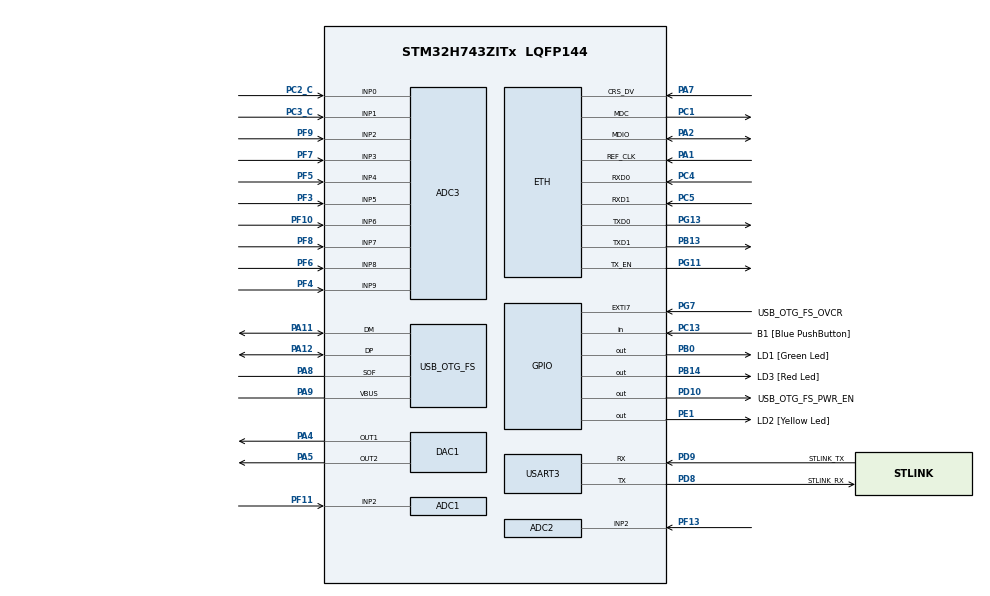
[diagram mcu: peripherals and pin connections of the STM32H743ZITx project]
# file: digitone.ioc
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ADC1.Channel-0\#ChannelRegularConversion=ADC_CHANNEL_2
ADC1.ExternalTrigConv=ADC_EXTERNALTRIG_T6_TRGO
ADC1.NbrOfConversionFlag=1
ADC1.OffsetNumber-0\#ChannelRegularConversion=ADC_OFFSET_NONE
ADC1.OffsetSignedSaturation-0\#ChannelRegularConversion=DISABLE
ADC1.Rank-0\#ChannelRegularConversion=1
ADC1.SamplingTime-0\#ChannelRegularConversion=ADC_SAMPLETIME_1CYCLE_5
ADC1.master=1
ADC2.Channel-0\#ChannelRegularConversion=ADC_CHANNEL_2
ADC2.ExternalTrigConv=ADC_EXTERNALTRIG_T6_TRGO
ADC2.NbrOfConversionFlag=1
ADC2.OffsetNumber-0\#ChannelRegularConversion=ADC_OFFSET_NONE
ADC2.OffsetSignedSaturation-0\#ChannelRegularConversion=DISABLE
ADC2.Rank-0\#ChannelRegularConversion=1
ADC2.SamplingTime-0\#ChannelRegularConversion=ADC_SAMPLETIME_1CYCLE_5
ADC3.Channel-0\#ChannelRegularConversion=ADC_CHANNEL_0
ADC3.Channel-1\#ChannelRegularConversion=ADC_CHANNEL_1
ADC3.Channel-2\#ChannelRegularConversion=ADC_CHANNEL_2
ADC3.Channel-3\#ChannelRegularConversion=ADC_CHANNEL_3
ADC3.Channel-4\#ChannelRegularConversion=ADC_CHANNEL_4
ADC3.Channel-5\#ChannelRegularConversion=ADC_CHANNEL_5
ADC3.Channel-6\#ChannelRegularConversion=ADC_CHANNEL_6
ADC3.Channel-7\#ChannelRegularConversion=ADC_CHANNEL_7
ADC3.Channel-8\#ChannelRegularConversion=ADC_CHANNEL_8
ADC3.Channel-9\#ChannelRegularConversion=ADC_CHANNEL_9
ADC3.EOCSelection=ADC_EOC_SEQ_CONV
ADC3.ExternalTrigConv=ADC_EXTERNALTRIG_T3_TRGO
ADC3.NbrOfConversion=10
ADC3.NbrOfConversionFlag=1
ADC3.OffsetNumber-0\#ChannelRegularConversion=ADC_OFFSET_NONE
ADC3.OffsetNumber-1\#ChannelRegularConversion=ADC_OFFSET_NONE
ADC3.OffsetNumber-2\#ChannelRegularConversion=ADC_OFFSET_NONE
ADC3.OffsetNumber-3\#ChannelRegularConversion=ADC_OFFSET_NONE
ADC3.OffsetNumber-4\#ChannelRegularConversion=ADC_OFFSET_NONE
ADC3.OffsetNumber-5\#ChannelRegularConversion=ADC_OFFSET_NONE
ADC3.OffsetNumber-6\#ChannelRegularConversion=ADC_OFFSET_NONE
ADC3.OffsetNumber-7\#ChannelRegularConversion=ADC_OFFSET_NONE
ADC3.OffsetNumber-8\#ChannelRegularConversion=ADC_OFFSET_NONE
ADC3.OffsetNumber-9\#ChannelRegularConversion=ADC_OFFSET_NONE
ADC3.OffsetSignedSaturation-0\#ChannelRegularConversion=DISABLE
ADC3.OffsetSignedSaturation-1\#ChannelRegularConversion=DISABLE
ADC3.OffsetSignedSaturation-2\#ChannelRegularConversion=DISABLE
ADC3.OffsetSignedSaturation-3\#ChannelRegularConversion=DISABLE
ADC3.OffsetSignedSaturation-4\#ChannelRegularConversion=DISABLE
ADC3.OffsetSignedSaturation-5\#ChannelRegularConversion=DISABLE
ADC3.OffsetSignedSaturation-6\#ChannelRegularConversion=DISABLE
ADC3.OffsetSignedSaturation-7\#ChannelRegularConversion=DISABLE
ADC3.OffsetSignedSaturation-8\#ChannelRegularConversion=DISABLE
ADC3.OffsetSignedSaturation-9\#ChannelRegularConversion=DISABLE
ADC3.Rank-0\#ChannelRegularConversion=1
ADC3.Rank-1\#ChannelRegularConversion=2
ADC3.Rank-2\#ChannelRegularConversion=3
ADC3.Rank-3\#ChannelRegularConversion=4
ADC3.Rank-4\#ChannelRegularConversion=5
ADC3.Rank-5\#ChannelRegularConversion=6
ADC3.Rank-6\#ChannelRegularConversion=7
ADC3.Rank-7\#ChannelRegularConversion=8
ADC3.Rank-8\#ChannelRegularConversion=9
ADC3.Rank-9\#ChannelRegularConversion=10
ADC3.SamplingTime-0\#ChannelRegularConversion=ADC_SAMPLETIME_1CYCLE_5
ADC3.SamplingTime-1\#ChannelRegularConversion=ADC_SAMPLETIME_1CYCLE_5
ADC3.SamplingTime-2\#ChannelRegularConversion=ADC_SAMPLETIME_1CYCLE_5
ADC3.SamplingTime-3\#ChannelRegularConversion=ADC_SAMPLETIME_1CYCLE_5
ADC3.SamplingTime-4\#ChannelRegularConversion=ADC_SAMPLETIME_1CYCLE_5
ADC3.SamplingTime-5\#ChannelRegularConversion=ADC_SAMPLETIME_1CYCLE_5
ADC3.SamplingTime-6\#ChannelRegularConversion=ADC_SAMPLETIME_1CYCLE_5
ADC3.SamplingTime-7\#ChannelRegularConversion=ADC_SAMPLETIME_1CYCLE_5
ADC3.SamplingTime-8\#ChannelRegularConversion=ADC_SAMPLETIME_1CYCLE_5
ADC3.SamplingTime-9\#ChannelRegularConversion=ADC_SAMPLETIME_1CYCLE_5
Bdma.ADC3.0.Direction=DMA_PERIPH_TO_MEMORY
Bdma.ADC3.0.EventEnable=DISABLE
Bdma.ADC3.0.Instance=BDMA_Channel0
Bdma.ADC3.0.MemDataAlignment=DMA_MDATAALIGN_HALFWORD
Bdma.ADC3.0.MemInc=DMA_MINC_ENABLE
Bdma.ADC3.0.Mode=DMA_CIRCULAR
Bdma.ADC3.0.PeriphDataAlignment=DMA_PDATAALIGN_HALFWORD
Bdma.ADC3.0.PeriphInc=DMA_PINC_DISABLE
Bdma.ADC3.0.Polarity=HAL_DMAMUX_REQ_GEN_RISING
Bdma.ADC3.0.Priority=DMA_PRIORITY_LOW
Bdma.ADC3.0.RequestNumber=1
Bdma.ADC3.0.SignalID=NONE
Bdma.ADC3.0.SyncEnable=DISABLE
Bdma.ADC3.0.SyncPolarity=HAL_DMAMUX_SYNC_NO_EVENT
Bdma.ADC3.0.SyncRequestNumber=1
Bdma.ADC3.0.SyncSignalID=NONE
Bdma.Request0=ADC3
Bdma.RequestsNb=1
DAC1.DAC_Channel-DAC_OUT1=DAC_CHANNEL_1
DAC1.DAC_Channel-DAC_OUT2=DAC_CHANNEL_2
Dma.ADC1.0.Direction=DMA_PERIPH_TO_MEMORY
Dma.ADC1.0.EventEnable=DISABLE
Dma.ADC1.0.FIFOMode=DMA_FIFOMODE_DISABLE
Dma.ADC1.0.Instance=DMA1_Stream0
Dma.ADC1.0.MemDataAlignment=DMA_MDATAALIGN_HALFWORD
Dma.ADC1.0.MemInc=DMA_MINC_ENABLE
Dma.ADC1.0.Mode=DMA_CIRCULAR
Dma.ADC1.0.PeriphDataAlignment=DMA_PDATAALIGN_HALFWORD
Dma.ADC1.0.PeriphInc=DMA_PINC_DISABLE
Dma.ADC1.0.Polarity=HAL_DMAMUX_REQ_GEN_RISING
Dma.ADC1.0.Priority=DMA_PRIORITY_LOW
Dma.ADC1.0.RequestNumber=1
Dma.ADC1.0.SignalID=NONE
Dma.ADC1.0.SyncEnable=DISABLE
Dma.ADC1.0.SyncPolarity=HAL_DMAMUX_SYNC_NO_EVENT
Dma.ADC1.0.SyncRequestNumber=1
Dma.ADC1.0.SyncSignalID=NONE
Dma.ADC2.1.Direction=DMA_PERIPH_TO_MEMORY
Dma.ADC2.1.EventEnable=DISABLE
Dma.ADC2.1.FIFOMode=DMA_FIFOMODE_DISABLE
Dma.ADC2.1.Instance=DMA1_Stream1
Dma.ADC2.1.MemDataAlignment=DMA_MDATAALIGN_HALFWORD
Dma.ADC2.1.MemInc=DMA_MINC_ENABLE
Dma.ADC2.1.Mode=DMA_CIRCULAR
Dma.ADC2.1.PeriphDataAlignment=DMA_PDATAALIGN_HALFWORD
Dma.ADC2.1.PeriphInc=DMA_PINC_DISABLE
Dma.ADC2.1.Polarity=HAL_DMAMUX_REQ_GEN_RISING
Dma.ADC2.1.Priority=DMA_PRIORITY_HIGH
Dma.ADC2.1.RequestNumber=1
Dma.ADC2.1.SignalID=NONE
Dma.ADC2.1.SyncEnable=DISABLE
Dma.ADC2.1.SyncPolarity=HAL_DMAMUX_SYNC_NO_EVENT
Dma.ADC2.1.SyncRequestNumber=1
Dma.ADC2.1.SyncSignalID=NONE
Dma.DAC1_CH1.2.Direction=DMA_MEMORY_TO_PERIPH
Dma.DAC1_CH1.2.EventEnable=DISABLE
Dma.DAC1_CH1.2.FIFOMode=DMA_FIFOMODE_DISABLE
Dma.DAC1_CH1.2.Instance=DMA1_Stream2
Dma.DAC1_CH1.2.MemDataAlignment=DMA_MDATAALIGN_HALFWORD
Dma.DAC1_CH1.2.MemInc=DMA_MINC_ENABLE
Dma.DAC1_CH1.2.Mode=DMA_CIRCULAR
Dma.DAC1_CH1.2.PeriphDataAlignment=DMA_PDATAALIGN_HALFWORD
Dma.DAC1_CH1.2.PeriphInc=DMA_PINC_DISABLE
Dma.DAC1_CH1.2.Polarity=HAL_DMAMUX_REQ_GEN_RISING
Dma.DAC1_CH1.2.Priority=DMA_PRIORITY_HIGH
Dma.DAC1_CH1.2.RequestNumber=1
Dma.DAC1_CH1.2.SignalID=NONE
Dma.DAC1_CH1.2.SyncEnable=DISABLE
Dma.DAC1_CH1.2.SyncPolarity=HAL_DMAMUX_SYNC_NO_EVENT
Dma.DAC1_CH1.2.SyncRequestNumber=1
Dma.DAC1_CH1.2.SyncSignalID=NONE
Dma.DAC1_CH2.3.Direction=DMA_MEMORY_TO_PERIPH
Dma.DAC1_CH2.3.EventEnable=DISABLE
Dma.DAC1_CH2.3.FIFOMode=DMA_FIFOMODE_DISABLE
Dma.DAC1_CH2.3.Instance=DMA1_Stream3
Dma.DAC1_CH2.3.MemDataAlignment=DMA_MDATAALIGN_HALFWORD
Dma.DAC1_CH2.3.MemInc=DMA_MINC_ENABLE
Dma.DAC1_CH2.3.Mode=DMA_CIRCULAR
Dma.DAC1_CH2.3.PeriphDataAlignment=DMA_PDATAALIGN_HALFWORD
Dma.DAC1_CH2.3.PeriphInc=DMA_PINC_DISABLE
Dma.DAC1_CH2.3.Polarity=HAL_DMAMUX_REQ_GEN_RISING
Dma.DAC1_CH2.3.Priority=DMA_PRIORITY_LOW
Dma.DAC1_CH2.3.RequestNumber=1
Dma.DAC1_CH2.3.SignalID=NONE
Dma.DAC1_CH2.3.SyncEnable=DISABLE
Dma.DAC1_CH2.3.SyncPolarity=HAL_DMAMUX_SYNC_NO_EVENT
Dma.DAC1_CH2.3.SyncRequestNumber=1
Dma.DAC1_CH2.3.SyncSignalID=NONE
Dma.Request0=ADC1
Dma.Request1=ADC2
Dma.Request2=DAC1_CH1
Dma.Request3=DAC1_CH2
ETH.MediaInterface=HAL_ETH_RMII_MODE
Mcu.Family=STM32H7
Mcu.Name=STM32H743ZITx
Mcu.Package=LQFP144
NVIC.BDMA_Channel0_IRQn=true\:0\:0\:false\:false\:true\:false\:true\:true
NVIC.DMA1_Stream0_IRQn=true\:0\:0\:false\:false\:true\:false\:true\:true
NVIC.DMA1_Stream1_IRQn=true\:0\:0\:false\:false\:true\:false\:true\:true
NVIC.DMA1_Stream2_IRQn=true\:0\:0\:false\:false\:true\:false\:true\:true
NVIC.DMA1_Stream3_IRQn=true\:0\:0\:false\:false\:true\:false\:true\:true
NVIC.PriorityGroup=NVIC_PRIORITYGROUP_4
PA1.Mode=RMII
PA1.Signal=ETH_REF_CLK
PA11.Mode=Device_Only
PA11.Signal=USB_OTG_FS_DM
PA12.Mode=Device_Only
PA12.Signal=USB_OTG_FS_DP
PA2.Mode=RMII
PA2.Signal=ETH_MDIO
PA4.Signal=COMP_DAC11_group
PA5.Signal=COMP_DAC12_group
PA7.Mode=RMII
PA7.Signal=ETH_CRS_DV
PA8.Mode=Activate_SOF_FS
PA8.Signal=USB_OTG_FS_SOF
PA9.Mode=Activate_VBUS
PA9.Signal=USB_OTG_FS_VBUS
PB0.GPIO_Label=LD1 [Green Led]
PB0.Signal=GPIO_Output
PB13.Mode=RMII
PB13.Signal=ETH_TXD1
PB14.GPIO_Label=LD3 [Red Led]
PB14.Signal=GPIO_Output
PC1.Mode=RMII
PC1.Signal=ETH_MDC
PC13.GPIO_Label=B1 [Blue PushButton]
PC13.Signal=GPIO_Input
PC14-OSC32_IN\ (OSC32_IN).Mode=LSE-External-Oscillator
PC14-OSC32_IN\ (OSC32_IN).Signal=RCC_OSC32_IN
PC15-OSC32_OUT\ (OSC32_OUT).Mode=LSE-External-Oscillator
PC15-OSC32_OUT\ (OSC32_OUT).Signal=RCC_OSC32_OUT
PC2_C.Mode=IN0-Single-Ended
PC2_C.Signal=ADC3_INP0
PC3_C.Mode=IN1-Single-Ended
PC3_C.Signal=ADC3_INP1
PC4.Mode=RMII
PC4.Signal=ETH_RXD0
PC5.Mode=RMII
PC5.Signal=ETH_RXD1
PD10.GPIO_Label=USB_OTG_FS_PWR_EN
PD10.Signal=GPIO_Output
PD8.GPIO_Label=STLINK_RX
PD8.Mode=Asynchronous
PD8.Signal=USART3_TX
PD9.GPIO_Label=STLINK_TX
PD9.Mode=Asynchronous
PD9.Signal=USART3_RX
PE1.GPIO_Label=LD2 [Yellow Led]
PE1.Signal=GPIO_Output
PF10.Mode=IN6-Single-Ended
PF10.Signal=ADC3_INP6
PF11.Mode=IN2-Single-Ended
PF11.Signal=ADC1_INP2
PF13.Mode=IN2-Single-Ended
PF13.Signal=ADC2_INP2
PF3.Mode=IN5-Single-Ended
PF3.Signal=ADC3_INP5
PF4.Mode=IN9-Single-Ended
PF4.Signal=ADC3_INP9
PF5.Mode=IN4-Single-Ended
PF5.Signal=ADC3_INP4
PF6.Mode=IN8-Single-Ended
PF6.Signal=ADC3_INP8
PF7.Mode=IN3-Single-Ended
PF7.Signal=ADC3_INP3
PF8.Mode=IN7-Single-Ended
PF8.Signal=ADC3_INP7
PF9.Mode=IN2-Single-Ended
PF9.Signal=ADC3_INP2
PG11.Mode=RMII
PG11.Signal=ETH_TX_EN
PG13.Mode=RMII
PG13.Signal=ETH_TXD0
PG7.GPIO_Label=USB_OTG_FS_OVCR
PG7.Signal=GPXTI7
PH0-OSC_IN\ (PH0).Mode=HSE-External-Clock-Source
PH0-OSC_IN\ (PH0).Signal=RCC_OSC_IN
PH1-OSC_OUT\ (PH1).Signal=RCC_OSC_OUT
ProjectManager.HeapSize=0x200
ProjectManager.StackSize=0x400
ProjectManager.TargetToolchain=STM32CubeIDE
RCC.ADCFreq_Value=76000000
RCC.APB1Freq_Value=64000000
RCC.APB2Freq_Value=64000000
RCC.APB3Freq_Value=64000000
RCC.APB4Freq_Value=64000000
RCC.CortexFreq_Value=64000000
RCC.DIVM1=1
RCC.DIVM2=1
RCC.DIVN1=24
RCC.DIVN2=19
RCC.DIVQ1=4
RCC.HCLKFreq_Value=64000000
RCC.HSE_VALUE=8000000
RCC.PLLFRACN=0
RCC.PWR_Regulator_Voltage_Scale=PWR_REGULATOR_VOLTAGE_SCALE2
RCC.SYSCLKFreq_VALUE=64000000
RCC.USBFreq_Value=48000000
SH.COMP_DAC11_group.0=DAC1_OUT1,DAC_OUT1
SH.COMP_DAC12_group.0=DAC1_OUT2,DAC_OUT2
TIM3.Period=1024-1
TIM3.Prescaler=64-1
TIM3.TIM_MasterOutputTrigger=TIM_TRGO_UPDATE
TIM6.Period=128-1
TIM6.Prescaler=8-1
TIM6.TIM_MasterOutputTrigger=TIM_TRGO_UPDATE
USART3.VirtualMode-Asynchronous=VM_ASYNC
USB_OTG_FS.VirtualMode=Device_Only
VP_TIM3_VS_ClockSourceINT.Mode=Internal
VP_TIM6_VS_ClockSourceINT.Mode=Enable_Timer
board=NUCLEO-H743ZI2

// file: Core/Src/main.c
/* USER CODE BEGIN Header */
/**
  ******************************************************************************
  * @file           : main.c
  * @brief          : Main program body
  ******************************************************************************
  * @attention
  *
  * Copyright (c) 2024 STMicroelectronics.
  * All rights reserved.
  *
  * This software is licensed under terms that can be found in the LICENSE file
  * in the root directory of this software component.
  * If no LICENSE file comes with this software, it is provided AS-IS.
  *
  ******************************************************************************
  */
/* USER CODE END Header */
#include "main.h"
#include "adc.h"
#include "bdma.h"
#include "dac.h"
#include "dma.h"
#include "eth.h"
#include "tim.h"
#include "usart.h"
#include "usb_otg.h"
#include "gpio.h"

/* USER CODE BEGIN Includes */
#include "app.h"
/* USER CODE END Includes */

void SystemClock_Config(void);
void PeriphCommonClock_Config(void);

int main(void)
{

  /* MCU Configuration--------------------------------------------------------*/

  /* Reset of all peripherals, Initializes the Flash interface and the Systick. */
  HAL_Init();

  /* Configure the system clock */
  SystemClock_Config();

/* Configure the peripherals common clocks */
  PeriphCommonClock_Config();

  /* Initialize all configured peripherals */
  MX_GPIO_Init();
  MX_DMA_Init();
  MX_BDMA_Init();
  MX_USB_OTG_FS_PCD_Init();
  MX_ADC1_Init();
  MX_ETH_Init();
  MX_TIM6_Init();
  MX_USART3_UART_Init();
  MX_DAC1_Init();
  MX_ADC3_Init();
  MX_ADC2_Init();
  MX_TIM3_Init();
  /* USER CODE BEGIN 2 */
  initApp();
  /* USER CODE END 2 */

  /* Infinite loop */
  while (1)
  {

  }
}

void SystemClock_Config(void)
{
  RCC_OscInitTypeDef RCC_OscInitStruct = {0};
  RCC_ClkInitTypeDef RCC_ClkInitStruct = {0};

  /** Supply configuration update enable
  */
  HAL_PWREx_ConfigSupply(PWR_LDO_SUPPLY);

  /** Configure the main internal regulator output voltage
  */
  __HAL_PWR_VOLTAGESCALING_CONFIG(PWR_REGULATOR_VOLTAGE_SCALE2);

  while(!__HAL_PWR_GET_FLAG(PWR_FLAG_VOSRDY)) {}

  /** Initializes the RCC Oscillators according to the specified parameters
  * in the RCC_OscInitTypeDef structure.
  */
  RCC_OscInitStruct.OscillatorType = RCC_OSCILLATORTYPE_HSI|RCC_OSCILLATORTYPE_HSE;
  RCC_OscInitStruct.HSEState = RCC_HSE_BYPASS;
  RCC_OscInitStruct.HSIState = RCC_HSI_DIV1;
  RCC_OscInitStruct.HSICalibrationValue = RCC_HSICALIBRATION_DEFAULT;
  RCC_OscInitStruct.PLL.PLLState = RCC_PLL_ON;
  RCC_OscInitStruct.PLL.PLLSource = RCC_PLLSOURCE_HSE;
  RCC_OscInitStruct.PLL.PLLM = 1;
  RCC_OscInitStruct.PLL.PLLN = 24;
  RCC_OscInitStruct.PLL.PLLP = 2;
  RCC_OscInitStruct.PLL.PLLQ = 4;
  RCC_OscInitStruct.PLL.PLLR = 2;
  RCC_OscInitStruct.PLL.PLLRGE = RCC_PLL1VCIRANGE_3;
  RCC_OscInitStruct.PLL.PLLVCOSEL = RCC_PLL1VCOWIDE;
  RCC_OscInitStruct.PLL.PLLFRACN = 0;
  if (HAL_RCC_OscConfig(&RCC_OscInitStruct) != HAL_OK)
  {
    Error_Handler();
  }

  /** Initializes the CPU, AHB and APB buses clocks
  */
  RCC_ClkInitStruct.ClockType = RCC_CLOCKTYPE_HCLK|RCC_CLOCKTYPE_SYSCLK
                              |RCC_CLOCKTYPE_PCLK1|RCC_CLOCKTYPE_PCLK2
                              |RCC_CLOCKTYPE_D3PCLK1|RCC_CLOCKTYPE_D1PCLK1;
  RCC_ClkInitStruct.SYSCLKSource = RCC_SYSCLKSOURCE_HSI;
  RCC_ClkInitStruct.SYSCLKDivider = RCC_SYSCLK_DIV1;
  RCC_ClkInitStruct.AHBCLKDivider = RCC_HCLK_DIV1;
  RCC_ClkInitStruct.APB3CLKDivider = RCC_APB3_DIV1;
  RCC_ClkInitStruct.APB1CLKDivider = RCC_APB1_DIV1;
  RCC_ClkInitStruct.APB2CLKDivider = RCC_APB2_DIV1;
  RCC_ClkInitStruct.APB4CLKDivider = RCC_APB4_DIV1;

  if (HAL_RCC_ClockConfig(&RCC_ClkInitStruct, FLASH_LATENCY_1) != HAL_OK)
  {
    Error_Handler();
  }
}

void PeriphCommonClock_Config(void)
{
  RCC_PeriphCLKInitTypeDef PeriphClkInitStruct = {0};

  /** Initializes the peripherals clock
  */
  PeriphClkInitStruct.PeriphClockSelection = RCC_PERIPHCLK_ADC;
  PeriphClkInitStruct.PLL2.PLL2M = 1;
  PeriphClkInitStruct.PLL2.PLL2N = 19;
  PeriphClkInitStruct.PLL2.PLL2P = 2;
  PeriphClkInitStruct.PLL2.PLL2Q = 2;
  PeriphClkInitStruct.PLL2.PLL2R = 2;
  PeriphClkInitStruct.PLL2.PLL2RGE = RCC_PLL2VCIRANGE_3;
  PeriphClkInitStruct.PLL2.PLL2VCOSEL = RCC_PLL2VCOMEDIUM;
  PeriphClkInitStruct.PLL2.PLL2FRACN = 0;
  PeriphClkInitStruct.AdcClockSelection = RCC_ADCCLKSOURCE_PLL2;
  if (HAL_RCCEx_PeriphCLKConfig(&PeriphClkInitStruct) != HAL_OK)
  {
    Error_Handler();
  }
}

void Error_Handler(void)
{
  __disable_irq();
  while (1)
  {
  }
}
